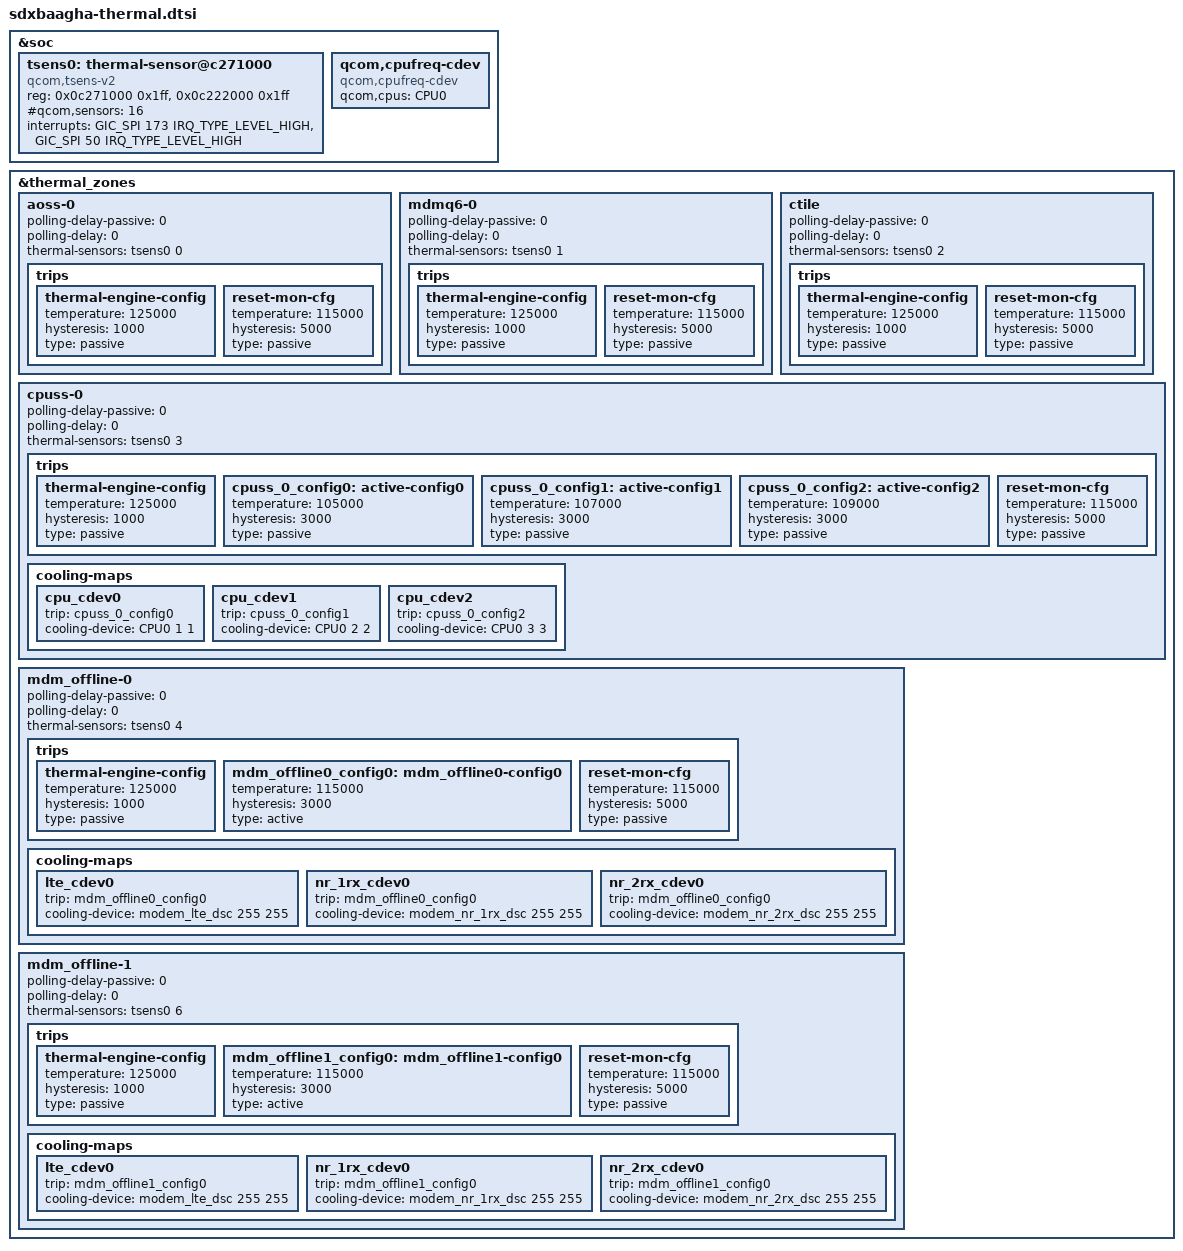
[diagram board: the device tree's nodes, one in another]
#include <dt-bindings/thermal/thermal_qti.h>

&soc {
	tsens0: thermal-sensor@c271000 {
		compatible = "qcom,tsens-v2";
		reg = <0x0c271000 0x1ff>, /* TM */
			<0x0c222000 0x1ff>; /* SROT */
		#qcom,sensors = <16>;
		interrupts = <GIC_SPI 173 IRQ_TYPE_LEVEL_HIGH>,
			<GIC_SPI 50 IRQ_TYPE_LEVEL_HIGH>;
		interrupt-names = "uplow","critical";
		#thermal-sensor-cells = <1>;
	};

	qcom,cpufreq-cdev {
		compatible = "qcom,cpufreq-cdev";
		qcom,cpus = <&CPU0>;
	};
};

#include "sdxbaagha-thermal-modem.dtsi"

&thermal_zones {
	aoss-0 {
		polling-delay-passive = <0>;
		polling-delay = <0>;
		thermal-sensors = <&tsens0 0>;
		trips {
			thermal-engine-config {
				temperature = <125000>;
				hysteresis = <1000>;
				type = "passive";
			};

			reset-mon-cfg {
				temperature = <115000>;
				hysteresis = <5000>;
				type = "passive";
			};
		};
	};

	mdmq6-0 {
		polling-delay-passive = <0>;
		polling-delay = <0>;
		thermal-sensors = <&tsens0 1>;
		trips {
			thermal-engine-config {
				temperature = <125000>;
				hysteresis = <1000>;
				type = "passive";
			};

			reset-mon-cfg {
				temperature = <115000>;
				hysteresis = <5000>;
				type = "passive";
			};
		};
	};

	ctile {
		polling-delay-passive = <0>;
		polling-delay = <0>;
		thermal-sensors = <&tsens0 2>;
		trips {
			thermal-engine-config {
				temperature = <125000>;
				hysteresis = <1000>;
				type = "passive";
			};

			reset-mon-cfg {
				temperature = <115000>;
				hysteresis = <5000>;
				type = "passive";
			};
		};
	};

	cpuss-0 {
		polling-delay-passive = <0>;
		polling-delay = <0>;
		thermal-sensors = <&tsens0 3>;
		trips {
			thermal-engine-config {
				temperature = <125000>;
				hysteresis = <1000>;
				type = "passive";
			};

			cpuss_0_config0: active-config0 {
				temperature = <105000>;
				hysteresis = <3000>;
				type = "passive";
			};

			cpuss_0_config1: active-config1 {
				temperature = <107000>;
				hysteresis = <3000>;
				type = "passive";
			};

			cpuss_0_config2: active-config2 {
				temperature = <109000>;
				hysteresis = <3000>;
				type = "passive";
			};

			reset-mon-cfg {
				temperature = <115000>;
				hysteresis = <5000>;
				type = "passive";
			};
		};

		cooling-maps {
			cpu_cdev0 {
				trip = <&cpuss_0_config0>;
				cooling-device = <&CPU0 1 1>;
			};

			cpu_cdev1 {
				trip = <&cpuss_0_config1>;
				cooling-device = <&CPU0 2 2>;
			};

			cpu_cdev2 {
				trip = <&cpuss_0_config2>;
				cooling-device = <&CPU0 3 3>;
			};
		};
	};

	mdm_offline-0 {
		polling-delay-passive = <0>;
		polling-delay = <0>;
		thermal-sensors = <&tsens0 4>;
		trips {
			thermal-engine-config {
				temperature = <125000>;
				hysteresis = <1000>;
				type = "passive";
			};

			mdm_offline0_config0: mdm_offline0-config0 {
				temperature = <115000>;
				hysteresis = <3000>;
				type = "active";
			};

			reset-mon-cfg {
				temperature = <115000>;
				hysteresis = <5000>;
				type = "passive";
			};
		};

		cooling-maps {
			lte_cdev0 {
				trip = <&mdm_offline0_config0>;
				cooling-device = <&modem_lte_dsc 255 255>;
			};

			nr_1rx_cdev0 {
				trip = <&mdm_offline0_config0>;
				cooling-device = <&modem_nr_1rx_dsc 255 255>;
			};

			nr_2rx_cdev0 {
				trip = <&mdm_offline0_config0>;
				cooling-device = <&modem_nr_2rx_dsc 255 255>;
			};
		};
	};

	mdm_offline-1 {
		polling-delay-passive = <0>;
		polling-delay = <0>;
		thermal-sensors = <&tsens0 6>;
		trips {
			thermal-engine-config {
				temperature = <125000>;
				hysteresis = <1000>;
				type = "passive";
			};

			mdm_offline1_config0: mdm_offline1-config0 {
				temperature = <115000>;
				hysteresis = <3000>;
				type = "active";
			};

			reset-mon-cfg {
				temperature = <115000>;
				hysteresis = <5000>;
				type = "passive";
			};
		};

		cooling-maps {
			lte_cdev0 {
				trip = <&mdm_offline1_config0>;
				cooling-device = <&modem_lte_dsc 255 255>;
			};

			nr_1rx_cdev0 {
				trip = <&mdm_offline1_config0>;
				cooling-device = <&modem_nr_1rx_dsc 255 255>;
			};

			nr_2rx_cdev0 {
				trip = <&mdm_offline1_config0>;
				cooling-device = <&modem_nr_2rx_dsc 255 255>;
			};
		};
	};
};

